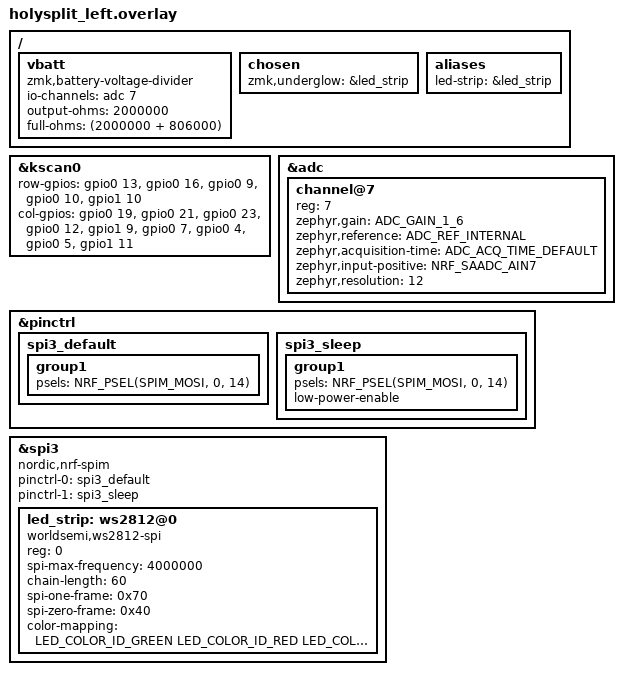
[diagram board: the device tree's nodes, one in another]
#include "holysplit.dtsi"
#include <dt-bindings/led/led.h>

&kscan0 {
	row-gpios
		= <&gpio0 13 (GPIO_ACTIVE_HIGH | GPIO_PULL_DOWN)>
		, <&gpio0 16 (GPIO_ACTIVE_HIGH | GPIO_PULL_DOWN)>
		, <&gpio0 9  (GPIO_ACTIVE_HIGH | GPIO_PULL_DOWN)>
		, <&gpio0 10 (GPIO_ACTIVE_HIGH | GPIO_PULL_DOWN)>
		, <&gpio1 10 (GPIO_ACTIVE_HIGH | GPIO_PULL_DOWN)>
		;
	
	col-gpios
		= <&gpio0 19 GPIO_ACTIVE_HIGH>
		, <&gpio0 21 GPIO_ACTIVE_HIGH>
		, <&gpio0 23 GPIO_ACTIVE_HIGH>
		, <&gpio0 12 GPIO_ACTIVE_HIGH>
		, <&gpio1 9  GPIO_ACTIVE_HIGH>
		, <&gpio0 7  GPIO_ACTIVE_HIGH>
		, <&gpio0 4  GPIO_ACTIVE_HIGH>
		, <&gpio0 5  GPIO_ACTIVE_HIGH>
		, <&gpio1 11 GPIO_ACTIVE_HIGH>
		;
};

/ {
	vbatt: vbatt {
		compatible = "zmk,battery-voltage-divider";
		io-channels = <&adc 7>;
		output-ohms = <2000000>;
		full-ohms = <(2000000 + 806000)>;
	};

	chosen {
		zmk,underglow = &led_strip;
	};

	aliases {
		led-strip = &led_strip;
	};
};

&adc {
	#address-cells = <1>;
	#size-cells = <0>;
	status = "okay";

	channel@7 {
		reg = <7>;
		zephyr,gain = "ADC_GAIN_1_6";
		zephyr,reference = "ADC_REF_INTERNAL";
		zephyr,acquisition-time = <ADC_ACQ_TIME_DEFAULT>;
		zephyr,input-positive = <NRF_SAADC_AIN7>;
		zephyr,resolution = <12>;
	};
};

&pinctrl {
	spi3_default: spi3_default {
		group1 {
			psels = <NRF_PSEL(SPIM_MOSI, 0, 14)>;
		};
	};

	spi3_sleep: spi3_sleep {
		group1 {
			psels = <NRF_PSEL(SPIM_MOSI, 0, 14)>;
			low-power-enable;
		};
	};
};

&spi3 {
	compatible = "nordic,nrf-spim";
	status = "okay";
	pinctrl-0 = <&spi3_default>;
	pinctrl-1 = <&spi3_sleep>;
	pinctrl-names = "default", "sleep";
	
	led_strip: ws2812@0 {
		compatible = "worldsemi,ws2812-spi";
		reg = <0>;
		spi-max-frequency = <4000000>;
		chain-length = <60>;
		spi-one-frame = <0x70>;
		spi-zero-frame = <0x40>;
		color-mapping = <LED_COLOR_ID_GREEN LED_COLOR_ID_RED LED_COLOR_ID_BLUE>;
	};
};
